# R9A09G057H register map
Vendor: Renesas Electronics; File version: 1.00
CPU: other r0p3, little endian, MPU, FPU, vendor SysTick, 4 interrupt priority bits, 480 interrupts
Registers are 32-bit, read-write, no defined reset value unless marked. A register's access mark holds for its fields unless they carry their own. Offsets are from the block's base; [hi:lo] are bit positions; lines under a group give offsets from that group; {n}, {i} and the like mark numbered series.

## R_ADC_E0 — IO define file for adc_e.
Base 0x11C00000
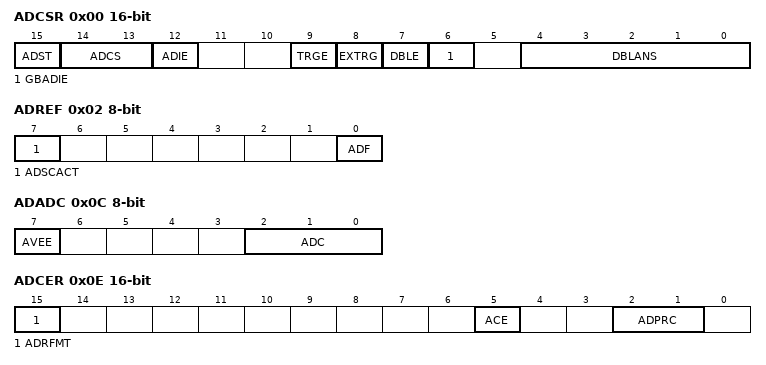
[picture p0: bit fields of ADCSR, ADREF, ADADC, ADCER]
0x00 ADCSR 16-bit
  [15] ADST, [14:13] ADCS, [12] ADIE, [9] TRGE, [8] EXTRG, [7] DBLE, [6] GBADIE, [4:0] DBLANS
0x02 ADREF 8-bit ro
  [7] ADSCACT, [0] ADF
0x04 ADANSA0 16-bit
  [7:0] ANSA0
0x08 ADADS0 16-bit
  [7:0] ADS0
0x0C ADADC 8-bit
  [7] AVEE, [2:0] ADC
0x0E ADCER 16-bit
  [15] ADRFMT, [5] ACE, [2:1] ADPRC
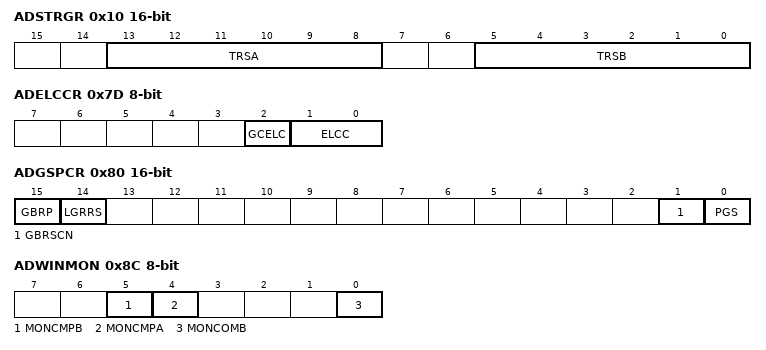
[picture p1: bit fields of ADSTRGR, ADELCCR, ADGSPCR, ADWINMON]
0x10 ADSTRGR 16-bit
  [13:8] TRSA, [5:0] TRSB
0x14 ADANSB0 16-bit
  [7:0] ANSB0
0x18 ADDBLDR 16-bit ro
  [15:0] DBLDR
{0x20+2i} ADDR{i} 16-bit ro (i=0..7)
  [15:0] DR
0x7D ADELCCR 8-bit
  [2] GCELC, [1:0] ELCC
0x80 ADGSPCR 16-bit
  [15] GBRP, [14] LGRRS, [1] GBRSCN, [0] PGS
0x84 ADDBLDRA 16-bit ro
  [15:0] DBLDRA
0x86 ADDBLDRB 16-bit ro
  [15:0] DBLDRB
0x8C ADWINMON 8-bit ro
  [5] MONCMPB, [4] MONCMPA, [0] MONCOMB
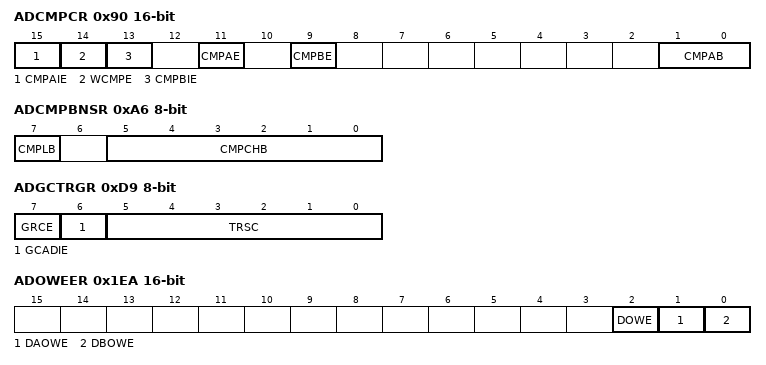
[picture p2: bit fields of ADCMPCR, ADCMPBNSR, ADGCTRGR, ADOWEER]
0x90 ADCMPCR 16-bit
  [15] CMPAIE, [14] WCMPE, [13] CMPBIE, [11] CMPAE, [9] CMPBE, [1:0] CMPAB
0x94 ADCMPANSR0 16-bit
  [7:0] CMPCHA0
0x98 ADCMPLR0 16-bit
  [7:0] CMPLCHA0
0x9C ADCMPDR0 16-bit
  [15:0] CMPLLA
0x9E ADCMPDR1 16-bit
  [15:0] CMPULA
0xA0 ADCMPSR0 16-bit
  [7:0] CMPSTCHA0
0xA6 ADCMPBNSR 8-bit
  [7] CMPLB, [5:0] CMPCHB
0xA8 ADWINLLB 16-bit
  [15:0] CMPLLB
0xAA ADWINULB 16-bit
  [15:0] CMPULB
0xAC ADCMPBSR 8-bit
  [0] CMPSTB
0xD4 ADANSC0 16-bit
  [7:0] ANSC0
0xD9 ADGCTRGR 8-bit
  [7] GRCE, [6] GCADIE, [5:0] TRSC
0x1E2 ADERCR 8-bit
  [2] OWEIE
0x1E3 ADERCLR 8-bit
  [2] OWEC
0x1E8 ADOWER 16-bit ro
  [7:0] OWE
0x1EA ADOWEER 16-bit ro
  [2] DOWE, [1] DAOWE, [0] DBOWE

## R_CMTW0 — IO define file for cmtw.
Base 0x11C01800
Same registers: R_CMTW1 0x11C01C00, R_CMTW2 0x11C02000, R_CMTW3 0x11C02400, R_CMTW4 0x13000C00, R_CMTW5 0x13001000, R_CMTW6 0x13001400, R_CMTW7 0x13001800
0x00 CMWSTR 16-bit
  [0] STR
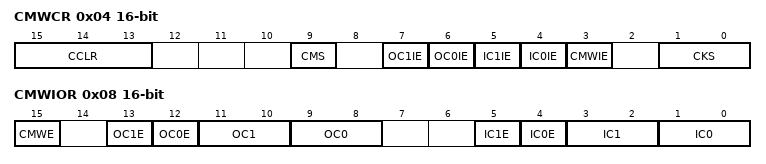
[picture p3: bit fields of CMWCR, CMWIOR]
0x04 CMWCR 16-bit
  [15:13] CCLR, [9] CMS, [7] OC1IE, [6] OC0IE, [5] IC1IE, [4] IC0IE, [3] CMWIE, [1:0] CKS
0x08 CMWIOR 16-bit
  [15] CMWE, [13] OC1E, [12] OC0E, [11:10] OC1, [9:8] OC0, [5] IC1E, [4] IC0E, [3:2] IC1, [1:0] IC0
0x10 CMWCNT
  [31:0] CNT
0x14 CMWCOR
  [31:0] COR
0x18 CMWICR0 ro
  [31:0] ICR
0x1C CMWICR1 ro
  [31:0] ICR
0x20 CMWOCR0
  [31:0] OCR
0x24 CMWOCR1
  [31:0] OCR

## R_CRC — IO define file for crc.
Base 0x13000800
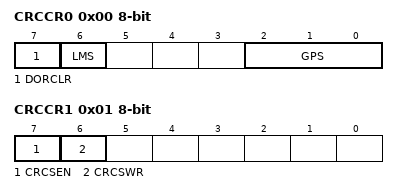
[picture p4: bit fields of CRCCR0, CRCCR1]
0x00 CRCCR0 8-bit
  [7] DORCLR wo, [6] LMS, [2:0] GPS
0x01 CRCCR1 8-bit
  [7] CRCSEN, [6] CRCSWR
0x04 CRCDIR
0x04 CRCDIR_BY 8-bit
0x08 CRCDOR
0x08 CRCDOR_HA 16-bit
0x08 CRCDOR_BY 8-bit
0x0C CRCSAR 16-bit
  [15:0] CRCSA

## R_DMAC_B0 — IO define file for dmac.
Base 0x11400000
Same registers: R_DMAC_B3 0x12000000, R_DMAC_B4 0x12010000, R_DMAC_B1 0x14830000, R_DMAC_B2 0x14840000
{0x0+0x400*i} GRP[{i}] (i=0..1) group — GRP register group
  {0x0+0x40*j} CH[{j}] (j=0..7) group — CH register group
    {0x0+0xC*k} N[{k}] (k=0..1) group — N register group
      0x00 SA
      0x04 DA
      0x08 TB
    0x18 CRSA ro
    0x1C CRDA ro
    0x20 CRTB ro
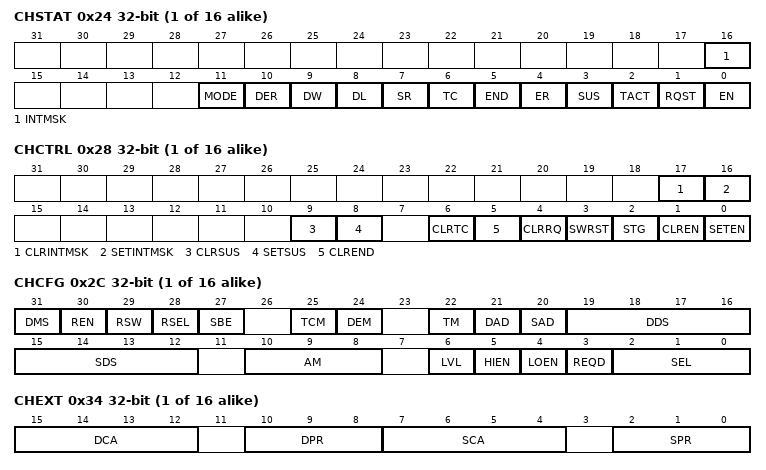
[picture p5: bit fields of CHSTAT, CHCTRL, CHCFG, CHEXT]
    0x24 CHSTAT ro
      [16] INTMSK, [11] MODE, [10] DER, [9] DW, [8] DL, [7] SR, [6] TC, [5] END, [4] ER, [3] SUS, [2] TACT, [1] RQST, [0] EN
    0x28 CHCTRL
      [17] CLRINTMSK, [16] SETINTMSK, [9] CLRSUS, [8] SETSUS, [6] CLRTC, [5] CLREND, [4] CLRRQ, [3] SWRST, [2] STG, [1] CLREN, [0] SETEN
    0x2C CHCFG
      [31] DMS, [30] REN, [29] RSW, [28] RSEL, [27] SBE, [25] TCM, [24] DEM, [22] TM, [21] DAD, [20] SAD, [19:16] DDS, [15:12] SDS, [10:8] AM, [6] LVL, [5] HIEN, [4] LOEN, [3] REQD, [2:0] SEL
    0x30 CHITVL
      [15:0] ITVL
    0x34 CHEXT
      [15:12] DCA, [10:8] DPR, [7:4] SCA, [2:0] SPR
    0x38 NXLA
    0x3C CRLA ro
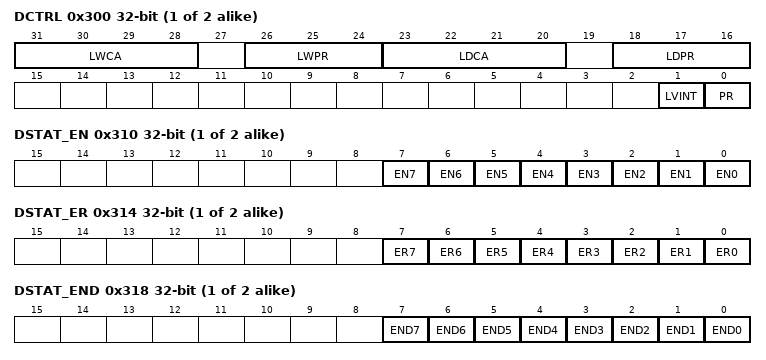
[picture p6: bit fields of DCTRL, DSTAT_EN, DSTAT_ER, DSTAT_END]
  0x300 DCTRL
    [31:28] LWCA, [26:24] LWPR, [23:20] LDCA, [18:16] LDPR, [1] LVINT, [0] PR
  0x310 DSTAT_EN ro
    [n] EN{n} (n=0..7)
  0x314 DSTAT_ER ro
    [n] ER{n} (n=0..7)
  0x318 DSTAT_END ro
    [n] END{n} (n=0..7)
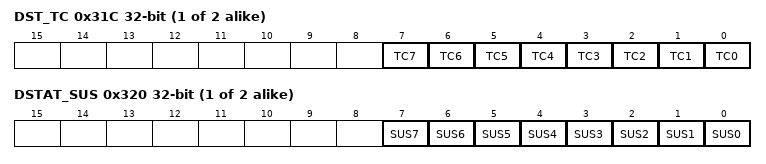
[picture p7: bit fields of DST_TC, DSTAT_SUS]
  0x31C DST_TC ro
    [n] TC{n} (n=0..7)
  0x320 DSTAT_SUS ro
    [n] SUS{n} (n=0..7)
